# AST1080 register map
File version: 1.0
CPU: CM4 r0p1, little endian, MPU, FPU, 4 interrupt priority bits, 256 interrupts
Registers are 32-bit, read-write, reset 0x0 unless marked. A register's access mark holds for its fields unless they carry their own. Offsets are from the block's base; [hi:lo] are bit positions; {n}, {i} and the like mark numbered series.

## gsram
Base 0x74B80000
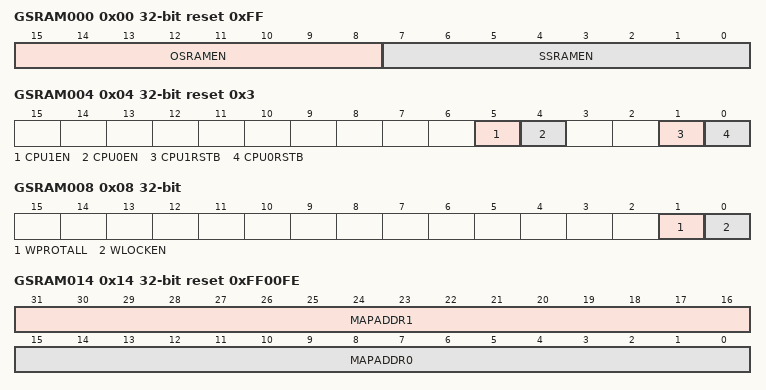
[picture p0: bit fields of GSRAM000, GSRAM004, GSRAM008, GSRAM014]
0x00 GSRAM000 reset 0xFF — GSRAM\_CTL
  [15:8] OSRAMEN, [7:0] SSRAMEN
0x04 GSRAM004 reset 0x3 — GSRAM\_INFO
  [5] CPU1EN, [4] CPU0EN, [1] CPU1RSTB ro, [0] CPU0RSTB ro
0x08 GSRAM008 — GSRAM\_WP
  [1] WPROTALL, [0] WLOCKEN
0x0C GSRAM00C — GSRAM\_GWLOCK
  [7:0] GWLOCK
0x10 GSRAM010 — GSRAM\_OADDR\_BASE
  [15:0] OADDRBASE
0x14 GSRAM014 reset 0xFF00FE — GSRAM\_MAP\_ADDR0
  [31:16] MAPADDR1, [15:0] MAPADDR0
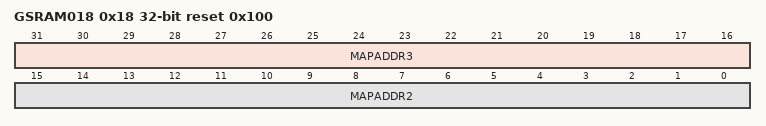
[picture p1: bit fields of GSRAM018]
0x18 GSRAM018 reset 0x100 — GSRAM\_MAP\_ADDR1
  [31:16] MAPADDR3, [15:0] MAPADDR2
0x80 GSRAM080 — GSRAM\_WLOCK00
  [31:0] WLOCK00
0x84 GSRAM084 — GSRAM\_WLOCK01
  [31:0] WLOCK01
0x88 GSRAM088 — GSRAM\_WLOCK02
  [31:0] WLOCK02
0x8C GSRAM08C — GSRAM\_WLOCK03
  [31:0] WLOCK03
0x90 GSRAM090 — GSRAM\_WLOCK04
  [31:0] WLOCK04
0x94 GSRAM094 — GSRAM\_WLOCK05
  [31:0] WLOCK05
0x98 GSRAM098 — GSRAM\_WLOCK06
  [31:0] WLOCK06
0x9C GSRAM09C — GSRAM\_WLOCK07
  [31:0] WLOCK07
0xA0 GSRAM0A0 — GSRAM\_WLOCK08
  [31:0] WLOCK08
0xA4 GSRAM0A4 — GSRAM\_WLOCK09
  [31:0] WLOCK09
0xA8 GSRAM0A8 — GSRAM\_WLOCK10
  [31:0] WLOCK10
0xAC GSRAM0AC — GSRAM\_WLOCK11
  [31:0] WLOCK11
0xB0 GSRAM0B0 — GSRAM\_WLOCK12
  [31:0] WLOCK12
0xB4 GSRAM0B4 — GSRAM\_WLOCK13
  [31:0] WLOCK13
0xB8 GSRAM0B8 — GSRAM\_WLOCK14
  [31:0] WLOCK14
0xBC GSRAM0BC — GSRAM\_WLOCK15
  [31:0] WLOCK15
0xC0 GSRAM0C0 — GSRAM\_WLOCK16
  [31:0] WLOCK16
0xC4 GSRAM0C4 — GSRAM\_WLOCK17
  [31:0] WLOCK17
0xC8 GSRAM0C8 — GSRAM\_WLOCK18
  [31:0] WLOCK18
0xCC GSRAM0CC — GSRAM\_WLOCK19
  [31:0] WLOCK19
0xD0 GSRAM0D0 — GSRAM\_WLOCK20
  [31:0] WLOCK20
0xD4 GSRAM0D4 — GSRAM\_WLOCK21
  [31:0] WLOCK21
0xD8 GSRAM0D8 — GSRAM\_WLOCK22
  [31:0] WLOCK22
0xDC GSRAM0DC — GSRAM\_WLOCK23
  [31:0] WLOCK23
0xE0 GSRAM0E0 — GSRAM\_WLOCK24
  [31:0] WLOCK24
0xE4 GSRAM0E4 — GSRAM\_WLOCK25
  [31:0] WLOCK25
0xE8 GSRAM0E8 — GSRAM\_WLOCK26
  [31:0] WLOCK26
0xEC GSRAM0EC — GSRAM\_WLOCK27
  [31:0] WLOCK27
0xF0 GSRAM0F0 — GSRAM\_WLOCK28
  [31:0] WLOCK28
0xF4 GSRAM0F4 — GSRAM\_WLOCK29
  [31:0] WLOCK29
0xF8 GSRAM0F8 — GSRAM\_WLOCK30
  [31:0] WLOCK30
0xFC GSRAM0FC — GSRAM\_WLOCK31
  [31:0] WLOCK31
0x100 GSRAM100 — GSRAM\_WLOCK32
  [31:0] WLOCK32
0x104 GSRAM104 — GSRAM\_WLOCK33
  [31:0] WLOCK33
0x108 GSRAM108 — GSRAM\_WLOCK34
  [31:0] WLOCK34
{0x6C+0x10*i} GSRAM{i}C (i=10..17) — GSRAM\_WLOCK{4i-5}
  [31:0] WLOCK{4i-5}
0x110 GSRAM110 — GSRAM\_WLOCK36
  [31:0] WLOCK36
0x114 GSRAM114 — GSRAM\_WLOCK37
  [31:0] WLOCK37
0x118 GSRAM118 — GSRAM\_WLOCK38
  [31:0] WLOCK38
0x120 GSRAM120 — GSRAM\_WLOCK40
  [31:0] WLOCK40
0x124 GSRAM124 — GSRAM\_WLOCK41
  [31:0] WLOCK41
0x128 GSRAM128 — GSRAM\_WLOCK42
  [31:0] WLOCK42
0x130 GSRAM130 — GSRAM\_WLOCK44
  [31:0] WLOCK44
0x134 GSRAM134 — GSRAM\_WLOCK45
  [31:0] WLOCK45
0x138 GSRAM138 — GSRAM\_WLOCK46
  [31:0] WLOCK46
0x140 GSRAM140 — GSRAM\_WLOCK48
  [31:0] WLOCK48
0x144 GSRAM144 — GSRAM\_WLOCK49
  [31:0] WLOCK49
0x148 GSRAM148 — GSRAM\_WLOCK50
  [31:0] WLOCK50
0x150 GSRAM150 — GSRAM\_WLOCK52
  [31:0] WLOCK52
0x154 GSRAM154 — GSRAM\_WLOCK53
  [31:0] WLOCK53
0x158 GSRAM158 — GSRAM\_WLOCK54
  [31:0] WLOCK54
0x160 GSRAM160 — GSRAM\_WLOCK56
  [31:0] WLOCK56
0x164 GSRAM164 — GSRAM\_WLOCK57
  [31:0] WLOCK57
0x168 GSRAM168 — GSRAM\_WLOCK58
  [31:0] WLOCK58
0x170 GSRAM170 — GSRAM\_WLOCK60
  [31:0] WLOCK60
0x174 GSRAM174 — GSRAM\_WLOCK61
  [31:0] WLOCK61
0x178 GSRAM178 — GSRAM\_WLOCK62
  [31:0] WLOCK62

## i2c_filter
Base 0x74C14000
0x00 I2C_FILTER000 — I2CFLT\_RST
  [0] TOPRST
0x08 I2C_FILTER008 — I2CFLT\_IRQEN
  [15:0] TOPIRQEN
0x0C I2C_FILTER00C — I2CFLT\_IRQSTA
  [15:0] TOPIRQSTA ro

## i2c_filter_thr
Base 0x74C14200
Same registers: i2c_filter_thr1 0x74C14300, i2c_filter_thr2 0x74C14400, i2c_filter_thr3 0x74C14500
0x00 I2C_FILTER_THR000 — I2CFLT\_THR0\_RST
  [0] RST
0x04 I2C_FILTER_THR004 — I2CFLT\_THR0\_EN
  [0] EN
0x08 I2C_FILTER_THR008 — I2CFLT\_THR0\_ADR
  [31:0] ADDR
0x0C I2C_FILTER_THR00C — I2CFLT\_THR0\_CFG
  [31:0] CFG
0x10 I2C_FILTER_THR010 — I2CFLT\_THR0\_TMR
  [31:0] TMRCFG
0x14 I2C_FILTER_THR014 — I2CFLT\_THR0\_INTEN
  [7:0] INTEN
0x18 I2C_FILTER_THR018 — I2CFLT\_THR0\_INTS
  [7:0] INTS
0x20 I2C_FILTER_THR020 — I2CFLT\_THR0\_STATUS
  [31:0] STATUS ro
0x24 I2C_FILTER_THR024 — I2CFLT\_THR0\_SEQ
  [31:0] RXSEQVAL ro
0x40 I2C_FILTER_THR040 — I2CFLT\_THR0\_MAP0
  [31:0] MAP0
0x44 I2C_FILTER_THR044 — I2CFLT\_THR0\_MAP1
  [31:0] MAP1
0x48 I2C_FILTER_THR048 — I2CFLT\_THR0\_MAP2
  [31:0] MAP2
0x4C I2C_FILTER_THR04C — I2CFLT\_THR0\_MAP3
  [31:0] MAP3
0x60 I2C_FILTER_THR060 — I2CFLT\_THR0\_INFO
  [31:0] INFO ro
0x70 I2C_FILTER_THR070 — I2CFLT\_THR0\_ADR\_HI
  [7:0] ADDRHI
0x7C I2C_FILTER_THR07C — I2CF\_ELOG\_CNT
  [7:0] ELOGCNT
0x80 I2C_FILTER_THR080 — I2CF\_ELOG00
  [31:0] ELOG00
0x84 I2C_FILTER_THR084 — I2CF\_ELOG01
  [31:0] ELOG01
0x88 I2C_FILTER_THR088 — I2CF\_ELOG02
  [31:0] ELOG02
0x8C I2C_FILTER_THR08C — I2CF\_ELOG03
  [31:0] ELOG03
0x90 I2C_FILTER_THR090 — I2CF\_ELOG04
  [31:0] ELOG04
0x94 I2C_FILTER_THR094 — I2CF\_ELOG05
  [31:0] ELOG05
0x98 I2C_FILTER_THR098 — I2CF\_ELOG06
  [31:0] ELOG06
0x9C I2C_FILTER_THR09C — I2CF\_ELOG07
  [31:0] ELOG07
